# psc3_p8_ppca register map
Vendor: Infineon Technologies; Series: PSC3_P8; File version: 1.0
CPU: CM33 r0p1, little endian, MPU, FPU, DSP, VTOR, 3 interrupt priority bits, 143 interrupts
Registers are 32-bit, read-write, reset 0x0 unless marked. A register's access mark holds for its fields unless they carry their own. Offsets are from the block's base; [hi:lo] are bit positions; lines under a group give offsets from that group.

## SVGS — SVGS Registers
Base 0x68260000
0x00 SVGS_MAIN group — SVGS Protected Runtime Registers (non-privileged SW accessible)
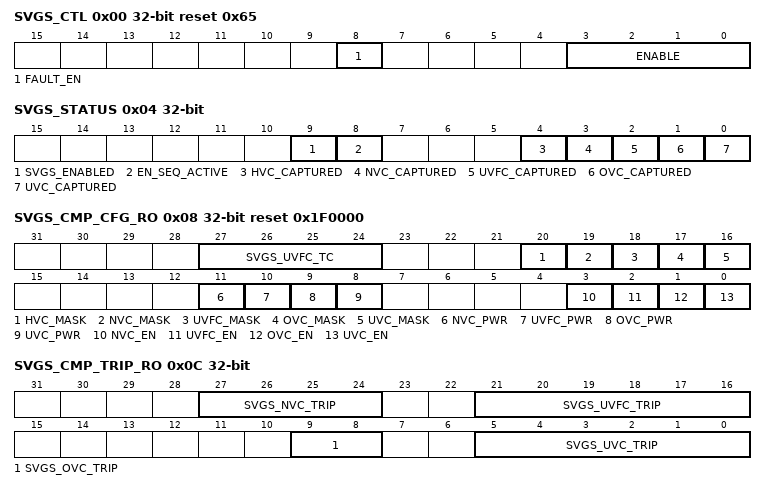
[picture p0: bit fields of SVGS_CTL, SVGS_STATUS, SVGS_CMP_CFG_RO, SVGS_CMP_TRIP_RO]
  0x00 SVGS_CTL reset 0x65 — SVGS Control Register
    [8] FAULT_EN — 0 = Disable Fault generation 1 = A fault will be generated to the CPUSS fault handler for any enabled comparator. Note that this fault will not be registered if the reset is not masked for the triggered comparator (reset takes precedence).
    [3:0] ENABLE — '0101' = Disable SVGS. All other values will enable SVGS. Note that HW will disable during DEEPSLEEP for power savings.
  0x04 SVGS_STATUS ro
    [9] SVGS_ENABLED — 1 = SVGS block enable sequence is complete and SVGS is functioning per loaded settings. 0 = Block is disabled, or in process of enable sequence.
    [8] EN_SEQ_ACTIVE — 1 = HW enable sequence is active. SW should check that this sequence has completed meaning SVGS is fully enabled before security critical operations.
    [4] HVC_CAPTURED — 1 = HVC (High Voltage Comparison function) occurred since last reset
    [3] NVC_CAPTURED — 1 = NVC (Noise Voltage Comparison function) occurred since last reset
    [2] UVFC_CAPTURED — 1 = UVFC (Under Voltage (Filtered) Comparison function) occurred since last reset
    [1] OVC_CAPTURED — 1 = OVC (Over Voltage Comparison function) occurred since last reset
    [0] UVC_CAPTURED — 1 = UVC (Under Voltage Comparison function) occurred since last reset
  0x08 SVGS_CMP_CFG_RO ro reset 0x1F0000 — SVGS Comparator Configuration
    [27:24] SVGS_UVFC_TC — Configures the time constant of the UVFC functionality. Each increment in setting sets increment (logarithmically equi-spaced) in time constant 0'h sets time constant 20ns 1'h sets time constant 24.4ns 2'h sets time constant 29.8ns 3'h sets time constant 36.4ns 4'h sets time constant 44.4ns 5'h sets time constant 54.3ns 6'h sets time constant 66.2ns 7'h sets time constant 81ns 8'h sets time constant 98.8ns A'h sets time constant 147.3ns B'h sets time constant 179.9ns C'h sets time constant 219.7ns D'h sets time constant 268.3ns E'h sets time constant 327.5ns F'h sets time constant 400ns
    [20] HVC_MASK — 1 = HVC masked from affecting svgs_glitch_event_hv
    [19] NVC_MASK — 1 = NVC masked from affecting svgs_glitch_event_hv
    [18] UVFC_MASK — 1 = UVFC masked from affecting svgs_glitch_event_hv
    [17] OVC_MASK — 1 = OVC masked from affecting svgs_glitch_event_hv
    [16] UVC_MASK — 1 = UVC masked from affecting svgs_glitch_event_hv
    [11] NVC_PWR — 1 = NVC in full power else half power mode
    [10] UVFC_PWR — 1 = UVFC in full power else half power mode
    [9] OVC_PWR — 1 = OVC in full power else half power mode
    [8] UVC_PWR — 1 = UVC in full power else half power mode
    [3] NVC_EN — 1 = Enable NVC (Noise Voltage Comparison function)
    [2] UVFC_EN — 1 = Enable UVFC (Under Voltage (Filtered) Comparison function)
    [1] OVC_EN — 1 = Enable OVC (Over Voltage Comparison function)
    [0] UVC_EN — 1 = Enable UVC (Under Voltage Comparison function)
  0x0C SVGS_CMP_TRIP_RO ro — SVGS Comparator trip-point configuration
    [27:24] SVGS_NVC_TRIP — Configures the threshold of NVC functionality in steps of 10mV. 0000 = 30mV 0001 = 40mV .... 1111 = 180mV
    [21:16] SVGS_UVFC_TRIP — Configures the threshold of UVFC functionality in steps of 6.2mV. 000000 = 760.00mV 000001 = 766.2mV .... 111111 = 1150mV
    [9:8] SVGS_OVC_TRIP — Configures the threshold of OVC functionality in steps of 25mV. 00 = 1250mV 01 = 1275mV 10 = 1300mV 11 = 1325mV
    [5:0] SVGS_UVC_TRIP — Configures the threshold of UVC functionality in steps of 6.2mV. 000000 = 760.00mV 000001 = 766.2mV .... 111111 = 1150mV
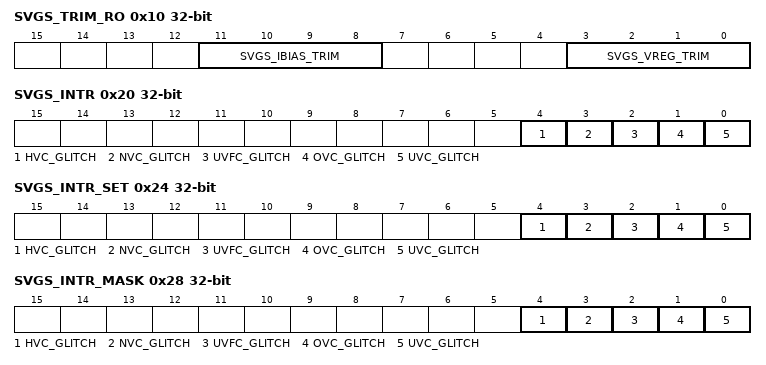
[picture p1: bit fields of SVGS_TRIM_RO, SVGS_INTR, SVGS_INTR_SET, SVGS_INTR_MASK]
  0x10 SVGS_TRIM_RO ro — SVGS Trim Register
    [11:8] SVGS_IBIAS_TRIM — Bias current output trim
    [3:0] SVGS_VREG_TRIM — Regulator output voltage trim
  0x20 SVGS_INTR — SVGS Interrupt Register
    [4] HVC_GLITCH write-1-clears — HVC Glitch detected interrupt
    [3] NVC_GLITCH write-1-clears — NVC Glitch detected interrupt
    [2] UVFC_GLITCH write-1-clears — UVFC Glitch detected interrupt
    [1] OVC_GLITCH write-1-clears — OVC Glitch detected interrupt
    [0] UVC_GLITCH write-1-clears — UVC Glitch detected interrupt
  0x24 SVGS_INTR_SET — SVGS Interrupt Set Register
    [4] HVC_GLITCH write-1-sets — Set interrupt for HVC_GLITCH interrupt.
    [3] NVC_GLITCH write-1-sets — Set interrupt for NVC_GLITCH interrupt.
    [2] UVFC_GLITCH write-1-sets — Set interrupt for UVFC_GLITCH interrupt.
    [1] OVC_GLITCH write-1-sets — Set interrupt for OVC_GLITCH interrupt.
    [0] UVC_GLITCH write-1-sets — Set interrupt for UVC_GLITCH interrupt.
  0x28 SVGS_INTR_MASK — SVGS Interrupt Mask Register
    [4] HVC_GLITCH — Mask for HVC_GLITCH interrupt.
    [3] NVC_GLITCH — Mask for NVC_GLITCH interrupt.
    [2] UVFC_GLITCH — Mask for UVFC_GLITCH interrupt.
    [1] OVC_GLITCH — Mask for OVC_GLITCH interrupt.
    [0] UVC_GLITCH — Mask for UVC_GLITCH interrupt.
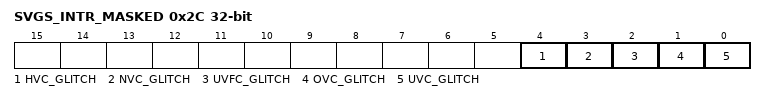
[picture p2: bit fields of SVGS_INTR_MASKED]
  0x2C SVGS_INTR_MASKED ro — SVGS Interrupt Masked Register
    [4] HVC_GLITCH — Logical and of corresponding request and mask bits.
    [3] NVC_GLITCH — Logical and of corresponding request and mask bits.
    [2] UVFC_GLITCH — Logical and of corresponding request and mask bits.
    [1] OVC_GLITCH — Logical and of corresponding request and mask bits.
    [0] UVC_GLITCH — Logical and of corresponding request and mask bits.
